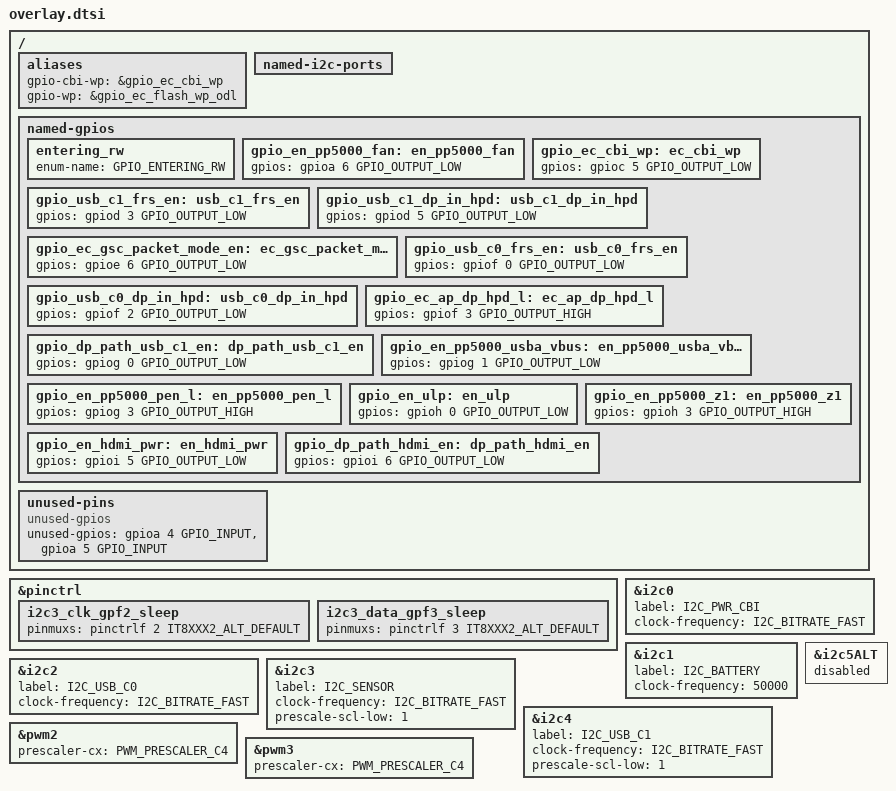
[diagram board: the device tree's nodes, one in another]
/* Copyright 2023 The ChromiumOS Authors
 * Use of this source code is governed by a BSD-style license that can be
 * found in the LICENSE file.
 *
 */

/ {
	aliases {
		gpio-cbi-wp = &gpio_ec_cbi_wp;
		gpio-wp = &gpio_ec_flash_wp_odl;
	};

	named-i2c-ports {
		/delete-node/ ec_i2c5;
	};

	named-gpios {
		/* unimplemented GPIOs */
		entering_rw: entering_rw {
			enum-name = "GPIO_ENTERING_RW";
		};
		/* default output level */
		gpio_en_pp5000_fan: en_pp5000_fan {
			gpios = <&gpioa 6 GPIO_OUTPUT_LOW>;
		};
		gpio_ec_cbi_wp: ec_cbi_wp {
			gpios = <&gpioc 5 GPIO_OUTPUT_LOW>;
		};
		gpio_usb_c1_frs_en: usb_c1_frs_en {
			gpios = <&gpiod 3 GPIO_OUTPUT_LOW>;
		};
		gpio_usb_c1_dp_in_hpd: usb_c1_dp_in_hpd {
			gpios = <&gpiod 5 GPIO_OUTPUT_LOW>;
		};
		gpio_ec_gsc_packet_mode_en: ec_gsc_packet_mode_en {
			gpios = <&gpioe 6 GPIO_OUTPUT_LOW>;
		};
		gpio_usb_c0_frs_en: usb_c0_frs_en {
			gpios = <&gpiof 0 GPIO_OUTPUT_LOW>;
		};
		gpio_usb_c0_dp_in_hpd: usb_c0_dp_in_hpd {
			gpios = <&gpiof 2 GPIO_OUTPUT_LOW>;
		};
		gpio_ec_ap_dp_hpd_l: ec_ap_dp_hpd_l {
			gpios = <&gpiof 3 GPIO_OUTPUT_HIGH>;
		};
		gpio_dp_path_usb_c1_en: dp_path_usb_c1_en {
			gpios = <&gpiog 0 GPIO_OUTPUT_LOW>;
		};
		gpio_en_pp5000_usba_vbus: en_pp5000_usba_vbus {
			gpios = <&gpiog 1 GPIO_OUTPUT_LOW>;
		};
		gpio_en_pp5000_pen_l: en_pp5000_pen_l {
			gpios = <&gpiog 3 GPIO_OUTPUT_HIGH>;
		};
		gpio_en_ulp: en_ulp {
			gpios = <&gpioh 0 GPIO_OUTPUT_LOW>;
		};
		gpio_en_pp5000_z1: en_pp5000_z1 {
			gpios = <&gpioh 3 GPIO_OUTPUT_HIGH>;
		};
		gpio_en_hdmi_pwr: en_hdmi_pwr {
			gpios = <&gpioi 5 GPIO_OUTPUT_LOW>;
		};
		gpio_dp_path_hdmi_en: dp_path_hdmi_en {
			gpios = <&gpioi 6 GPIO_OUTPUT_LOW>;
		};
	};

	unused-pins {
		compatible = "unused-gpios";

		unused-gpios =
			/* i2c5_scl */
			<&gpioa 4 GPIO_INPUT>,
			/* i2c5_sda */
			<&gpioa 5 GPIO_INPUT>;
	};
};

&pinctrl {
	i2c3_clk_gpf2_sleep: i2c3_clk_gpf2_sleep {
		pinmuxs = <&pinctrlf 2 IT8XXX2_ALT_DEFAULT>;
	};
	i2c3_data_gpf3_sleep: i2c3_data_gpf3_sleep {
		pinmuxs = <&pinctrlf 3 IT8XXX2_ALT_DEFAULT>;
	};
};

&i2c0 {
	label = "I2C_PWR_CBI";
	clock-frequency = <I2C_BITRATE_FAST>;
};

&i2c1 {
	label = "I2C_BATTERY";
	clock-frequency = <50000>;
};

&i2c2 {
	label = "I2C_USB_C0";
	clock-frequency = <I2C_BITRATE_FAST>;

};

&i2c3 {
	label = "I2C_SENSOR";
	clock-frequency = <I2C_BITRATE_FAST>;
	prescale-scl-low = <1>;
};

&i2c4 {
	label = "I2C_USB_C1";
	clock-frequency = <I2C_BITRATE_FAST>;
	prescale-scl-low = <1>;
};

&i2c5ALT {
	status = "disabled";
};

&pwm2 {
	prescaler-cx = <PWM_PRESCALER_C4>;
};

&pwm3 {
	prescaler-cx = <PWM_PRESCALER_C4>;
};
